AUTOSAR XML (schema 00048)
package /AdaptiveApplicationSwComponentTypes
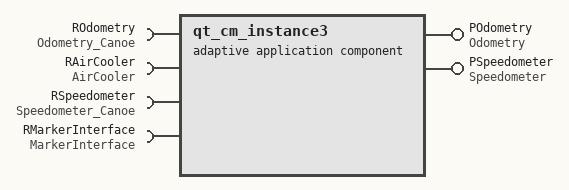
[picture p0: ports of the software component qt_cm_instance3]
  adaptive application sw component type qt_cm_instance3
    provide port POdometry: provided-interface=Odometry
    require port ROdometry: required-interface=Odometry_Canoe
    require port RAirCooler: required-interface=AirCooler
    provide port PSpeedometer: provided-interface=Speedometer
    require port RSpeedometer: required-interface=Speedometer_Canoe
    require port RMarkerInterface: required-interface=MarkerInterface
package /Executables
  executable qt_cm_instance3
    root sw component prototype rootSwComponentPrototype: application-type=qt_cm_instance3
